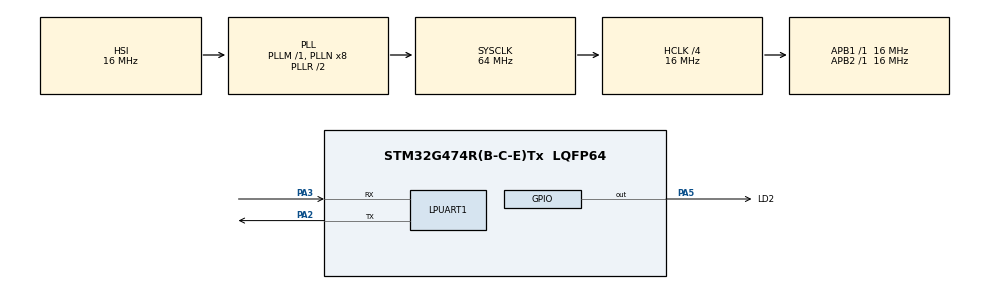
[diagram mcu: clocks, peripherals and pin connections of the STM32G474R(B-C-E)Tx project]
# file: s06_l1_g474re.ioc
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Mcu.Family=STM32G4
Mcu.Name=STM32G474R(B-C-E)Tx
Mcu.Package=LQFP64
NVIC.PriorityGroup=NVIC_PRIORITYGROUP_4
NVIC.TIM1_BRK_TIM15_IRQn=true\:15\:0\:false\:false\:true\:false\:true\:true
NVIC.TimeBase=TIM1_BRK_TIM15_IRQn
NVIC.TimeBaseIP=TIM15
PA13.Mode=Serial_Wire
PA13.Signal=SYS_JTMS-SWDIO
PA14.Mode=Serial_Wire
PA14.Signal=SYS_JTCK-SWCLK
PA2.Mode=Asynchronous
PA2.Signal=LPUART1_TX
PA3.Mode=Asynchronous
PA3.Signal=LPUART1_RX
PA5.GPIO_Label=LD2
PA5.Signal=GPIO_Output
ProjectManager.HeapSize=0x200
ProjectManager.StackSize=0x400
ProjectManager.TargetToolchain=STM32CubeIDE
RCC.ADC12Freq_Value=64000000
RCC.ADC345Freq_Value=64000000
RCC.AHBCLKDivider=RCC_SYSCLK_DIV4
RCC.AHBFreq_Value=16000000
RCC.APB1Freq_Value=16000000
RCC.APB1TimFreq_Value=16000000
RCC.APB2Freq_Value=16000000
RCC.APB2TimFreq_Value=16000000
RCC.CortexFreq_Value=16000000
RCC.EXTERNAL_CLOCK_VALUE=12288000
RCC.HCLKFreq_Value=16000000
RCC.HSE_VALUE=24000000
RCC.HSI48_VALUE=48000000
RCC.HSI_VALUE=16000000
RCC.LSE_VALUE=32768
RCC.RTCClockSelection=RCC_RTCCLKSOURCE_LSE
RCC.SYSCLKFreq_VALUE=64000000
RCC.SYSCLKSource=RCC_SYSCLKSOURCE_PLLCLK
RCC.USBFreq_Value=64000000
RCC.VCOOutputFreq_Value=128000000
VP_SYS_VS_DBSignals.Mode=DisableDeadBatterySignals
VP_SYS_VS_tim15.Mode=TIM15
board=NUCLEO-G474RE

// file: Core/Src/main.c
/* USER CODE BEGIN Header */
/**
  ******************************************************************************
  * @file           : main.c
  * @brief          : Main program body
  ******************************************************************************
  * @attention
  *
  * Copyright (c) 2026 STMicroelectronics.
  * All rights reserved.
  *
  * This software is licensed under terms that can be found in the LICENSE file
  * in the root directory of this software component.
  * If no LICENSE file comes with this software, it is provided AS-IS.
  *
  ******************************************************************************

  */
/* USER CODE END Header */
#include "main.h"

/* USER CODE BEGIN Includes */
#include <stdio.h>
#include <string.h>
#include "FreeRTOS.h"
#include "task.h"
#include <queue.h>
/* USER CODE END Includes */

UART_HandleTypeDef hlpuart1;

/* USER CODE BEGIN PV */
uint32_t cnt = 0;
UBaseType_t xWaterMark01 = 0, xWaterMark02 = 0;

QueueHandle_t xQueue = NULL;

/* USER CODE END PV */

void SystemClock_Config(void);
static void MX_GPIO_Init(void);
static void MX_LPUART1_UART_Init(void);

/* USER CODE BEGIN 0 */

/* Hardware realted functions */
void LedOn(){
	HAL_GPIO_WritePin(LD2_GPIO_Port, LD2_Pin, GPIO_PIN_SET);
}

void LedOff(){
	HAL_GPIO_WritePin(LD2_GPIO_Port, LD2_Pin, GPIO_PIN_RESET);
}

/* Local functions*/

/* Tasks */
void TaskSend(void *pvParams){
	uint32_t u32Send = 0;

	while (1){
		// retorna a quantidade mínima de espaço livre que restou na pilha
		xWaterMark01 = uxTaskGetStackHighWaterMark( NULL );

		// Armazenando o valor na fila
		if ( (xQueueSend(xQueue, &u32Send, (TickType_t) 0) ) == pdFAIL){
			Error_Handler();
		}

		u32Send++;
		LedOn();
		vTaskDelay(pdMS_TO_TICKS(1000));

	}
}

void TaskReceive(void *pvParams){
	uint32_t u32Recv = 0;
	while (1){
		// retorna a quantidade mínima de espaço livre que restou na pilha
		xWaterMark02 = uxTaskGetStackHighWaterMark( NULL );

		xQueueReceive(xQueue, &u32Recv, portMAX_DELAY);
		printf("Received value %lu\n", u32Recv);
		LedOff();

	}
}

/* Hooks*/
void vApplicationStackOverflowHook( TaskHandle_t xTask, char *pcTaskName ){
	Error_Handler();
}

/* USER CODE END 0 */

int main(void)
{

  /* USER CODE BEGIN 1 */
	TaskHandle_t TaskHandle01, TaskHandle02;
	BaseType_t xReturn;
	BaseType_t uxStackDepth = 256; // em words

  /* USER CODE END 1 */

  /* MCU Configuration--------------------------------------------------------*/

  /* Reset of all peripherals, Initializes the Flash interface and the Systick. */
  HAL_Init();

  /* Configure the system clock */
  SystemClock_Config();

  /* Initialize all configured peripherals */
  MX_GPIO_Init();
  MX_LPUART1_UART_Init();
  /* USER CODE BEGIN 2 */

  // Criando as task
  xReturn = xTaskCreate(TaskSend,
  		  "Task Send",
		  uxStackDepth,
  		  NULL,
  		  1,
  		  &TaskHandle01);

  if (xReturn != pdPASS){
    Error_Handler();
  }

  xReturn = xTaskCreate(TaskReceive,
  		  "Task Receive",
		  uxStackDepth,
  		  NULL,
  		  1,
  		  &TaskHandle02);

  if (xReturn != pdPASS){
    Error_Handler();
  }

  // Criando a fila
  xQueue = xQueueCreate(10, sizeof(uint32_t));

  /* USER CODE END 2 */

  /* Infinite loop */
  /* USER CODE BEGIN WHILE */

  // Inicializando o FreeRTOS
  vTaskStartScheduler();

  /* Never reaches here */
  while (1)
  {
    /* USER CODE END WHILE */

  }
}

void SystemClock_Config(void)
{
  RCC_OscInitTypeDef RCC_OscInitStruct = {0};
  RCC_ClkInitTypeDef RCC_ClkInitStruct = {0};

  /** Configure the main internal regulator output voltage
  */
  HAL_PWREx_ControlVoltageScaling(PWR_REGULATOR_VOLTAGE_SCALE1);

  /** Initializes the RCC Oscillators according to the specified parameters
  * in the RCC_OscInitTypeDef structure.
  */
  RCC_OscInitStruct.OscillatorType = RCC_OSCILLATORTYPE_HSI;
  RCC_OscInitStruct.HSIState = RCC_HSI_ON;
  RCC_OscInitStruct.HSICalibrationValue = RCC_HSICALIBRATION_DEFAULT;
  RCC_OscInitStruct.PLL.PLLState = RCC_PLL_ON;
  RCC_OscInitStruct.PLL.PLLSource = RCC_PLLSOURCE_HSI;
  RCC_OscInitStruct.PLL.PLLM = RCC_PLLM_DIV1;
  RCC_OscInitStruct.PLL.PLLN = 8;
  RCC_OscInitStruct.PLL.PLLP = RCC_PLLP_DIV2;
  RCC_OscInitStruct.PLL.PLLQ = RCC_PLLQ_DIV2;
  RCC_OscInitStruct.PLL.PLLR = RCC_PLLR_DIV2;
  if (HAL_RCC_OscConfig(&RCC_OscInitStruct) != HAL_OK)
  {
    Error_Handler();
  }

  /** Initializes the CPU, AHB and APB buses clocks
  */
  RCC_ClkInitStruct.ClockType = RCC_CLOCKTYPE_HCLK|RCC_CLOCKTYPE_SYSCLK
                              |RCC_CLOCKTYPE_PCLK1|RCC_CLOCKTYPE_PCLK2;
  RCC_ClkInitStruct.SYSCLKSource = RCC_SYSCLKSOURCE_PLLCLK;
  RCC_ClkInitStruct.AHBCLKDivider = RCC_SYSCLK_DIV4;
  RCC_ClkInitStruct.APB1CLKDivider = RCC_HCLK_DIV1;
  RCC_ClkInitStruct.APB2CLKDivider = RCC_HCLK_DIV1;

  if (HAL_RCC_ClockConfig(&RCC_ClkInitStruct, FLASH_LATENCY_0) != HAL_OK)
  {
    Error_Handler();
  }
}

static void MX_LPUART1_UART_Init(void)
{

  hlpuart1.Instance = LPUART1;
  hlpuart1.Init.BaudRate = 115200;
  hlpuart1.Init.WordLength = UART_WORDLENGTH_8B;
  hlpuart1.Init.StopBits = UART_STOPBITS_1;
  hlpuart1.Init.Parity = UART_PARITY_NONE;
  hlpuart1.Init.Mode = UART_MODE_TX_RX;
  hlpuart1.Init.HwFlowCtl = UART_HWCONTROL_NONE;
  hlpuart1.Init.OneBitSampling = UART_ONE_BIT_SAMPLE_DISABLE;
  hlpuart1.Init.ClockPrescaler = UART_PRESCALER_DIV1;
  hlpuart1.AdvancedInit.AdvFeatureInit = UART_ADVFEATURE_NO_INIT;
  if (HAL_UART_Init(&hlpuart1) != HAL_OK)
  {
    Error_Handler();
  }
  if (HAL_UARTEx_SetTxFifoThreshold(&hlpuart1, UART_TXFIFO_THRESHOLD_1_8) != HAL_OK)
  {
    Error_Handler();
  }
  if (HAL_UARTEx_SetRxFifoThreshold(&hlpuart1, UART_RXFIFO_THRESHOLD_1_8) != HAL_OK)
  {
    Error_Handler();
  }
  if (HAL_UARTEx_DisableFifoMode(&hlpuart1) != HAL_OK)
  {
    Error_Handler();
  }

}

static void MX_GPIO_Init(void)
{
  GPIO_InitTypeDef GPIO_InitStruct = {0};

  /* GPIO Ports Clock Enable */
  __HAL_RCC_GPIOA_CLK_ENABLE();

  /*Configure GPIO pin Output Level */
  HAL_GPIO_WritePin(LD2_GPIO_Port, LD2_Pin, GPIO_PIN_RESET);

  /*Configure GPIO pin : LD2_Pin */
  GPIO_InitStruct.Pin = LD2_Pin;
  GPIO_InitStruct.Mode = GPIO_MODE_OUTPUT_PP;
  GPIO_InitStruct.Pull = GPIO_NOPULL;
  GPIO_InitStruct.Speed = GPIO_SPEED_FREQ_LOW;
  HAL_GPIO_Init(LD2_GPIO_Port, &GPIO_InitStruct);

}

/* USER CODE BEGIN 4 */

// Redireciona os Prints para a USART
int __io_putchar(int ch){
	HAL_UART_Transmit(&hlpuart1, (uint8_t*)&ch, 1, HAL_MAX_DELAY);
	return ch;
}
/* USER CODE END 4 */

void HAL_TIM_PeriodElapsedCallback(TIM_HandleTypeDef *htim)
{
  if (htim->Instance == TIM15)
  {
    HAL_IncTick();
  }
}

void Error_Handler(void)
{
  __disable_irq();
  while (1)
  {
  }
}
